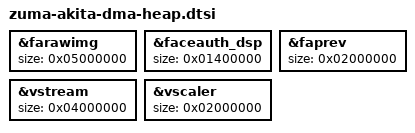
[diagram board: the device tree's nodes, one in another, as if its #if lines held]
// SPDX-License-Identifier: GPL-2.0-only
/*
 * DMA heap device tree entries specific to akita.
 *
 * Copyright 2023 Google,LLC
 *
 */
#include <linux/kconfig.h>

&farawimg {
	size = <0x05000000>; /* 80MB */
};

&faceauth_dsp {
	size = <0x01400000>; /* 20MB */
};

#if IS_ENABLED(CONFIG_ARM64_16K_PAGES)
// The minimum allocation for CMA is usually one huge page.
// The huge page size for 16kb page size config is 32MB.
// The reserved memory allocations have to be multiple of
// huge page size.
//
// See include/linux/pageblock-flags.h

&faprev {
        size = <0x02000000>; /* 32MB */
};

&vstream {
        size = <0x04000000>; /* 64MB */
};

&vscaler {
        size = <0x02000000>; /* 32MB */
};

#endif
